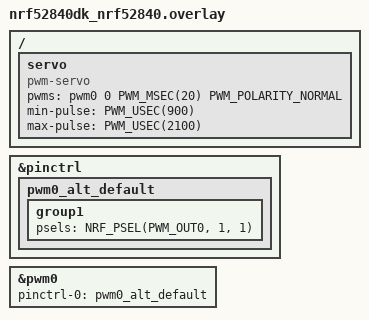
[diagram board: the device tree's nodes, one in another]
&pinctrl {
	pwm0_alt_default: pwm0_alt_default {
		group1 {
			psels = <NRF_PSEL(PWM_OUT0, 1, 1)>;
		};
	};
};

&pwm0 {
	pinctrl-0 = <&pwm0_alt_default>;
	/delete-property/ pinctrl-1;
	pinctrl-names = "default";
};


/ {
	servo: servo {
		compatible = "pwm-servo";
		pwms = <&pwm0 0 PWM_MSEC(20) PWM_POLARITY_NORMAL>;
		min-pulse = <PWM_USEC(900)>;
		max-pulse = <PWM_USEC(2100)>;
	};
};
